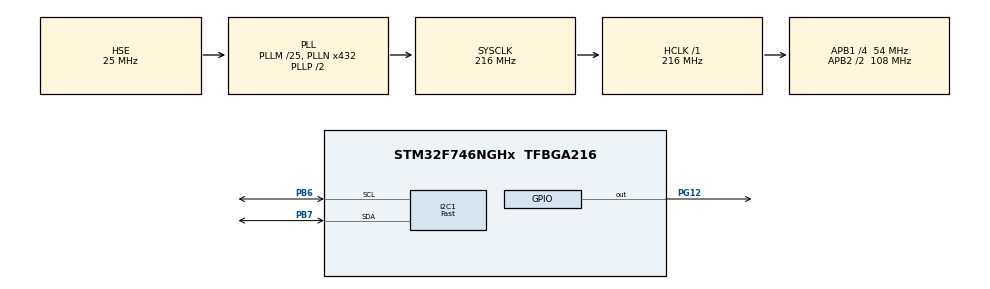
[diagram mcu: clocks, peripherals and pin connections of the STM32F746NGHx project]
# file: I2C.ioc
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I2C1.AddressingMode=I2C_ADDRESSINGMODE_7BIT
I2C1.I2C_Fall_Time=250
I2C1.I2C_Rise_Time=250
I2C1.I2C_Speed_Mode=I2C_Fast
I2C1.Timing=0x20630916
Mcu.Family=STM32F7
Mcu.Name=STM32F746NGHx
Mcu.Package=TFBGA216
NVIC.PriorityGroup=NVIC_PRIORITYGROUP_4
PB6.GPIO_Mode=GPIO_MODE_AF_OD
PB6.GPIO_Pu=GPIO_PULLUP
PB6.Mode=I2C
PB6.Signal=I2C1_SCL
PB7.GPIO_Pu=GPIO_PULLUP
PB7.Mode=I2C
PB7.Signal=I2C1_SDA
PG12.Signal=GPIO_Output
PH0/OSC_IN.Mode=HSE-External-Oscillator
PH0/OSC_IN.Signal=RCC_OSC_IN
PH1/OSC_OUT.Mode=HSE-External-Oscillator
PH1/OSC_OUT.Signal=RCC_OSC_OUT
ProjectManager.HeapSize=0x200
ProjectManager.StackSize=0x400
ProjectManager.TargetToolchain=STM32CubeIDE
RCC.AHBFreq_Value=216000000
RCC.APB1CLKDivider=RCC_HCLK_DIV4
RCC.APB1Freq_Value=54000000
RCC.APB1TimFreq_Value=108000000
RCC.APB2CLKDivider=RCC_HCLK_DIV2
RCC.APB2Freq_Value=108000000
RCC.APB2TimFreq_Value=216000000
RCC.CortexFreq_Value=216000000
RCC.HCLKFreq_Value=216000000
RCC.HSE_VALUE=25000000
RCC.HSI_VALUE=16000000
RCC.LSE_VALUE=32768
RCC.PLLM=25
RCC.PLLN=432
RCC.PLLSourceVirtual=RCC_PLLSOURCE_HSE
RCC.SYSCLKFreq_VALUE=216000000
RCC.SYSCLKSource=RCC_SYSCLKSOURCE_PLLCLK
RCC.USBFreq_Value=216000000
RCC.VCOOutputFreq_Value=432000000
board=custom

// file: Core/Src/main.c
/* USER CODE BEGIN Header */
/**
  ******************************************************************************
  * @file           : main.c
  * @brief          : Main program body
  ******************************************************************************
  * @attention
  *
  * Copyright (c) 2023 STMicroelectronics.
  * All rights reserved.
  *
  * This software is licensed under terms that can be found in the LICENSE file
  * in the root directory of this software component.
  * If no LICENSE file comes with this software, it is provided AS-IS.
  *
  ******************************************************************************
  */
/* USER CODE END Header */
#include "main.h"

/* USER CODE BEGIN Includes */
#include "string.h"
#include  "M24C08.h"
/* USER CODE END Includes */

I2C_HandleTypeDef hi2c1;

void SystemClock_Config(void);
static void MX_GPIO_Init(void);
static void MX_I2C1_Init(void);

/* USER CODE BEGIN 0 */

 /* uint8_t  dataW1[] = "Send the data to NVRAM for reading and writing the value";
  uint8_t  dataW2[] ={10,9,8,7,6,5,4,3,2,1};

  uint8_t  dataR1[60];
  uint8_t  dataR2[15];
  uint8_t  dataR3[5];

*/

/* USER CODE END 0 */

int main(void)
{

  /* MCU Configuration--------------------------------------------------------*/

  /* Reset of all peripherals, Initializes the Flash interface and the Systick. */
  HAL_Init();

  /* Configure the system clock */
  SystemClock_Config();

  /* Initialize all configured peripherals */
  MX_GPIO_Init();
  MX_I2C1_Init();
  /* USER CODE BEGIN 2 */
/*
  GENERIC_M24C08_WritePage(10 ,5 ,dataW2 ,strlen((char *)dataW2) , DEVICE_ID);

  GENERIC_M24C08_ReadPage(10 ,5 ,dataR1 ,60 ,DEVICE_ID);

  GENERIC_M24C08_WritePage(15 ,10 ,dataW1 ,strlen((char *)dataW1) ,AP_DEVICE_ID);

  GENERIC_M24C08_ReadPage(15 ,10 ,dataR2 ,30 ,AP_DEVICE_ID); */
  uint8_t data1[2];
 readTemp(0x93,0x00);
 HAL_I2C_Mem_Read(&hi2c1, 0x93, 0x07, 1, data1, 2, 100);

  /* USER CODE END 2 */

  /* Infinite loop */
  while (1)
  {

  }
}

void SystemClock_Config(void)
{
  RCC_OscInitTypeDef RCC_OscInitStruct = {0};
  RCC_ClkInitTypeDef RCC_ClkInitStruct = {0};

  /** Configure the main internal regulator output voltage
  */
  __HAL_RCC_PWR_CLK_ENABLE();
  __HAL_PWR_VOLTAGESCALING_CONFIG(PWR_REGULATOR_VOLTAGE_SCALE1);

  /** Initializes the RCC Oscillators according to the specified parameters
  * in the RCC_OscInitTypeDef structure.
  */
  RCC_OscInitStruct.OscillatorType = RCC_OSCILLATORTYPE_HSE;
  RCC_OscInitStruct.HSEState = RCC_HSE_ON;
  RCC_OscInitStruct.PLL.PLLState = RCC_PLL_ON;
  RCC_OscInitStruct.PLL.PLLSource = RCC_PLLSOURCE_HSE;
  RCC_OscInitStruct.PLL.PLLM = 25;
  RCC_OscInitStruct.PLL.PLLN = 432;
  RCC_OscInitStruct.PLL.PLLP = RCC_PLLP_DIV2;
  RCC_OscInitStruct.PLL.PLLQ = 2;
  if (HAL_RCC_OscConfig(&RCC_OscInitStruct) != HAL_OK)
  {
    Error_Handler();
  }

  /** Activate the Over-Drive mode
  */
  if (HAL_PWREx_EnableOverDrive() != HAL_OK)
  {
    Error_Handler();
  }

  /** Initializes the CPU, AHB and APB buses clocks
  */
  RCC_ClkInitStruct.ClockType = RCC_CLOCKTYPE_HCLK|RCC_CLOCKTYPE_SYSCLK
                              |RCC_CLOCKTYPE_PCLK1|RCC_CLOCKTYPE_PCLK2;
  RCC_ClkInitStruct.SYSCLKSource = RCC_SYSCLKSOURCE_PLLCLK;
  RCC_ClkInitStruct.AHBCLKDivider = RCC_SYSCLK_DIV1;
  RCC_ClkInitStruct.APB1CLKDivider = RCC_HCLK_DIV4;
  RCC_ClkInitStruct.APB2CLKDivider = RCC_HCLK_DIV2;

  if (HAL_RCC_ClockConfig(&RCC_ClkInitStruct, FLASH_LATENCY_7) != HAL_OK)
  {
    Error_Handler();
  }
}

static void MX_I2C1_Init(void)
{

  hi2c1.Instance = I2C1;
  hi2c1.Init.Timing = 0x20630916;
  hi2c1.Init.OwnAddress1 = 0;
  hi2c1.Init.AddressingMode = I2C_ADDRESSINGMODE_7BIT;
  hi2c1.Init.DualAddressMode = I2C_DUALADDRESS_DISABLE;
  hi2c1.Init.OwnAddress2 = 0;
  hi2c1.Init.OwnAddress2Masks = I2C_OA2_NOMASK;
  hi2c1.Init.GeneralCallMode = I2C_GENERALCALL_DISABLE;
  hi2c1.Init.NoStretchMode = I2C_NOSTRETCH_DISABLE;
  if (HAL_I2C_Init(&hi2c1) != HAL_OK)
  {
    Error_Handler();
  }

  /** Configure Analogue filter
  */
  if (HAL_I2CEx_ConfigAnalogFilter(&hi2c1, I2C_ANALOGFILTER_ENABLE) != HAL_OK)
  {
    Error_Handler();
  }

  /** Configure Digital filter
  */
  if (HAL_I2CEx_ConfigDigitalFilter(&hi2c1, 0) != HAL_OK)
  {
    Error_Handler();
  }

}

static void MX_GPIO_Init(void)
{
  GPIO_InitTypeDef GPIO_InitStruct = {0};

  /* GPIO Ports Clock Enable */
  __HAL_RCC_GPIOB_CLK_ENABLE();
  __HAL_RCC_GPIOG_CLK_ENABLE();
  __HAL_RCC_GPIOH_CLK_ENABLE();

  /*Configure GPIO pin Output Level */
  HAL_GPIO_WritePin(GPIOG, GPIO_PIN_12, GPIO_PIN_RESET);

  /*Configure GPIO pin : PG12 */
  GPIO_InitStruct.Pin = GPIO_PIN_12;
  GPIO_InitStruct.Mode = GPIO_MODE_OUTPUT_PP;
  GPIO_InitStruct.Pull = GPIO_NOPULL;
  GPIO_InitStruct.Speed = GPIO_SPEED_FREQ_LOW;
  HAL_GPIO_Init(GPIOG, &GPIO_InitStruct);

}

void Error_Handler(void)
{
  __disable_irq();
  while (1)
  {
  }
}
